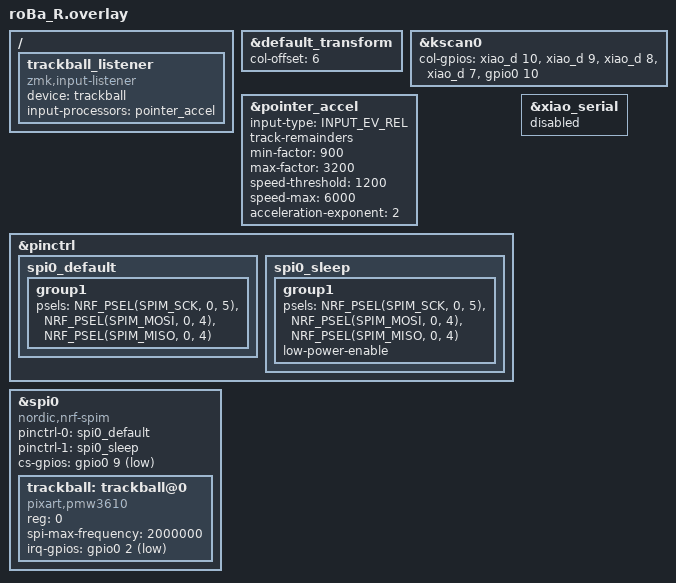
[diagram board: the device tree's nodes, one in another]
#include "roBa.dtsi"
#include <input/processors.dtsi>
#include <behaviors/input_gestures_accel.dtsi>

&default_transform {
    col-offset = <6>;
};

&kscan0 {
        col-gpios
            = <&xiao_d 10 GPIO_ACTIVE_HIGH>
            , <&xiao_d 9 GPIO_ACTIVE_HIGH>
            , <&xiao_d 8 GPIO_ACTIVE_HIGH>
            , <&xiao_d 7 GPIO_ACTIVE_HIGH>
            , <&gpio0 10 GPIO_ACTIVE_HIGH>
            ;
};

/* Pointer acceleration config: input-listener より前に置く */
&pointer_accel {
    input-type = <INPUT_EV_REL>;   /* トラックボールなので REL */
    track-remainders;              /* 微小移動の精度UP */
    min-factor = <900>;            /* 0.9x：低速は精密寄り */
    max-factor = <3200>;           /* 3.2x：高速時だけ速く */
    speed-threshold = <1200>;      /* 加速し始める速度 */
    speed-max = <6000>;            /* ここで最大加速 */
    acceleration-exponent = <2>;   /* 2=二次カーブ */
};

/ {
    trackball_listener {
        status = "okay";
        compatible = "zmk,input-listener";
        device = <&trackball>;
        input-processors = <&pointer_accel>;
    };
};

&pinctrl {
    spi0_default: spi0_default {
        group1 {
            psels = <NRF_PSEL(SPIM_SCK, 0, 5)>,
                <NRF_PSEL(SPIM_MOSI, 0, 4)>,
                <NRF_PSEL(SPIM_MISO, 0, 4)>;
        };
    };

    spi0_sleep: spi0_sleep {
        group1 {
            psels = <NRF_PSEL(SPIM_SCK, 0, 5)>,
                <NRF_PSEL(SPIM_MOSI, 0, 4)>,
                <NRF_PSEL(SPIM_MISO, 0, 4)>;
            low-power-enable;
        };
    };
};

&xiao_serial { status = "disabled"; };

&spi0 {
    status = "okay";
    compatible = "nordic,nrf-spim";
    pinctrl-0 = <&spi0_default>;
    pinctrl-1 = <&spi0_sleep>;
    pinctrl-names = "default", "sleep";
    cs-gpios = <&gpio0 9 GPIO_ACTIVE_LOW>;

    trackball: trackball@0 {
        status = "okay";
        compatible = "pixart,pmw3610";
        reg = <0>;
        spi-max-frequency = <2000000>;
        irq-gpios = <&gpio0 2 (GPIO_ACTIVE_LOW | GPIO_PULL_UP)>;
    };
};
